AUTOSAR XML (schema 4-0-3)
standard types defined: UInt32, UInt8
package /AUTOSAR_Platform/DataConstrs
  range DC_UInt8: raw 0..255
package /PATAC/MSM/ComponentTypes
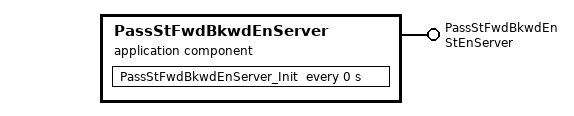
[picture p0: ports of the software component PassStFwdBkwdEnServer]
  application sw component type PassStFwdBkwdEnServer
    provide port PassStFwdBkwdEn: provided-com-specs=[{operation=Clear, queue-length=1}, {operation=Get, queue-length=1}, {operation=Set, queue-length=1}], provided-interface=StEnServer
    behavior PassStFwdBkwdEnServer_InternalBehavior
      operation invoked event OIT_PassStFwdBkwdEn_Clear_PassStFwdBkwdEn_Clear: start-on-event=PassStFwdBkwdEn_Clear, operation=PassStFwdBkwdEn.Clear
      operation invoked event OIT_PassStFwdBkwdEn_Get_PassStFwdBkwdEn_Get: start-on-event=PassStFwdBkwdEn_Get, operation=PassStFwdBkwdEn.Get
      operation invoked event OIT_PassStFwdBkwdEn_Set_PassStFwdBkwdEn_Set: start-on-event=PassStFwdBkwdEn_Set, operation=PassStFwdBkwdEn.Set
      timing event PassStFwdBkwdEnServer_InitEvent: start-on-event=PassStFwdBkwdEnServer_Init, period=0
      4 x runnable:
        PassStFwdBkwdEn_Clear
        PassStFwdBkwdEn_Get
        PassStFwdBkwdEn_Set
        PassStFwdBkwdEnServer_Init
  swc implementation PassStFwdBkwdEnServer_Implementation: behavior=PassStFwdBkwdEnServer_InternalBehavior
    code-descriptors:
      code Default: artifact-descriptors=autosar-engineering-object={short-label=Default, category=SWSRC}
package /PATAC/MSM/ModeAdjust/PortInterface
  client server interface StEnServer
    operation Clear
      arg data: type=UInt8, direction=IN, server-argument-impl-policy=USE-ARGUMENT-TYPE
    operation Get
      arg data: type=UInt32, direction=OUT, server-argument-impl-policy=USE-ARGUMENT-TYPE
    operation Set
      arg data: type=UInt8, direction=IN, server-argument-impl-policy=USE-ARGUMENT-TYPE
